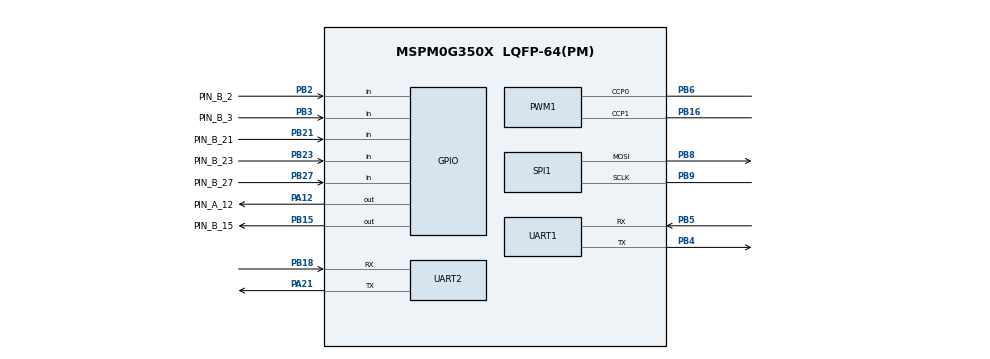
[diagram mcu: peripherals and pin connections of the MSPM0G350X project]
/**
 * @cliArgs --device "MSPM0G350X" --part "Default" --package "LQFP-64(PM)" --product "mspm0_sdk@2.05.01.00"
 * @versions {"tool":"1.24.0+4110"}
 */

/**
 * Import the modules used in this configuration.
 */
const GPIO   = scripting.addModule("/ti/driverlib/GPIO", {}, false);
const GPIO1  = GPIO.addInstance();
const GPIO2  = GPIO.addInstance();
const GPIO3  = GPIO.addInstance();
const GPIO4  = GPIO.addInstance();
const GPIO5  = GPIO.addInstance();
const GPIO6  = GPIO.addInstance();
const PWM    = scripting.addModule("/ti/driverlib/PWM", {}, false);
const PWM1   = PWM.addInstance();
const SPI    = scripting.addModule("/ti/driverlib/SPI", {}, false);
const SPI1   = SPI.addInstance();
const SYSCTL = scripting.addModule("/ti/driverlib/SYSCTL");
const UART   = scripting.addModule("/ti/driverlib/UART", {}, false);
const UART1  = UART.addInstance();
const UART2  = UART.addInstance();

/**
 * Write custom configuration values to the imported modules.
 */
const divider9       = system.clockTree["UDIV"];
divider9.divideValue = 2;

const gate7  = system.clockTree["MFCLKGATE"];
gate7.enable = true;

const mux4       = system.clockTree["EXHFMUX"];
mux4.inputSelect = "EXHFMUX_XTAL";

const mux8       = system.clockTree["HSCLKMUX"];
mux8.inputSelect = "HSCLKMUX_SYSPLL2X";

const mux12       = system.clockTree["SYSPLLMUX"];
mux12.inputSelect = "zSYSPLLMUX_HFCLK";

const pinFunction4       = system.clockTree["HFXT"];
pinFunction4.inputFreq   = 40;
pinFunction4.enable      = true;
pinFunction4.HFXTStartup = 10;

GPIO1.port                          = "PORTB";
GPIO1.$name                         = "GPIO_GRP_LED";
GPIO1.associatedPins[0].assignedPin = "22";
GPIO1.associatedPins[0].$name       = "PIN_B_22";

const Board = scripting.addModule("/ti/driverlib/Board", {}, false);

GPIO2.$name                          = "GPIO_GRP_MOTOR";
GPIO2.associatedPins.create(2);
GPIO2.associatedPins[0].$name        = "PIN_A_12";
GPIO2.associatedPins[0].assignedPort = "PORTA";
GPIO2.associatedPins[0].assignedPin  = "12";
GPIO2.associatedPins[0].pin.$assign  = "PA12";
GPIO2.associatedPins[1].$name        = "PIN_B_15";
GPIO2.associatedPins[1].assignedPort = "PORTB";
GPIO2.associatedPins[1].assignedPin  = "15";
GPIO2.associatedPins[1].pin.$assign  = "PB15";

GPIO3.$name                         = "GPIO_GRP_IRS";
GPIO3.port                          = "PORTA";
GPIO3.associatedPins.create(4);
GPIO3.associatedPins[0].assignedPin = "23";
GPIO3.associatedPins[0].$name       = "PIN_A_24";
GPIO3.associatedPins[1].assignedPin = "25";
GPIO3.associatedPins[1].$name       = "PIN_A_25";
GPIO3.associatedPins[2].assignedPin = "27";
GPIO3.associatedPins[2].$name       = "PIN_A_26";
GPIO3.associatedPins[3].direction   = "INPUT";
GPIO3.associatedPins[3].assignedPin = "29";
GPIO3.associatedPins[3].$name       = "PIN_A_27";

GPIO4.$name                         = "GPIO_GRP_LCD";
GPIO4.port                          = "PORTB";
GPIO4.associatedPins.create(4);
GPIO4.associatedPins[0].assignedPin = "10";
GPIO4.associatedPins[0].ioStructure = "SD";
GPIO4.associatedPins[0].$name       = "PIN_B_10";
GPIO4.associatedPins[1].assignedPin = "11";
GPIO4.associatedPins[1].ioStructure = "SD";
GPIO4.associatedPins[1].$name       = "PIN_B_11";
GPIO4.associatedPins[2].assignedPin = "14";
GPIO4.associatedPins[2].ioStructure = "SD";
GPIO4.associatedPins[2].$name       = "PIN_B_14";
GPIO4.associatedPins[3].assignedPin = "26";
GPIO4.associatedPins[3].ioStructure = "SD";
GPIO4.associatedPins[3].$name       = "PIN_B_26";

GPIO5.$name                         = "GPIO_GRP_ENCODER";
GPIO5.port                          = "PORTB";
GPIO5.associatedPins.create(4);
GPIO5.associatedPins[0].$name       = "PIN_B_2";
GPIO5.associatedPins[0].assignedPin = "2";
GPIO5.associatedPins[0].direction   = "INPUT";
GPIO5.associatedPins[0].interruptEn = true;
GPIO5.associatedPins[0].polarity    = "RISE";
GPIO5.associatedPins[0].pin.$assign = "PB2";
GPIO5.associatedPins[1].$name       = "PIN_B_3";
GPIO5.associatedPins[1].assignedPin = "3";
GPIO5.associatedPins[1].direction   = "INPUT";
GPIO5.associatedPins[1].pin.$assign = "PB3";
GPIO5.associatedPins[2].$name       = "PIN_B_23";
GPIO5.associatedPins[2].assignedPin = "23";
GPIO5.associatedPins[2].direction   = "INPUT";
GPIO5.associatedPins[2].interruptEn = true;
GPIO5.associatedPins[2].polarity    = "RISE";
GPIO5.associatedPins[2].pin.$assign = "PB23";
GPIO5.associatedPins[3].$name       = "PIN_B_27";
GPIO5.associatedPins[3].assignedPin = "27";
GPIO5.associatedPins[3].direction   = "INPUT";
GPIO5.associatedPins[3].pin.$assign = "PB27";

GPIO6.$name                              = "GPIO_GRP_KEY";
GPIO6.port                               = "PORTB";
GPIO6.associatedPins[0].$name            = "PIN_B_21";
GPIO6.associatedPins[0].assignedPin      = "21";
GPIO6.associatedPins[0].direction        = "INPUT";
GPIO6.associatedPins[0].internalResistor = "PULL_UP";
GPIO6.associatedPins[0].pin.$assign      = "PB21";

PWM1.$name                      = "PWM_0";
PWM1.clockPrescale              = 20;
PWM1.pwmMode                    = "EDGE_ALIGN_UP";
PWM1.clockDivider               = 2;
PWM1.peripheral.$assign         = "TIMG8";
PWM1.peripheral.ccp0Pin.$assign = "PB6";
PWM1.peripheral.ccp1Pin.$assign = "PB16";
PWM1.PWM_CHANNEL_0.$name        = "ti_driverlib_pwm_PWMTimerCC0";
PWM1.PWM_CHANNEL_1.$name        = "ti_driverlib_pwm_PWMTimerCC1";
PWM1.ccp0PinConfig.$name        = "ti_driverlib_gpio_GPIOPinGeneric2";
PWM1.ccp1PinConfig.$name        = "ti_driverlib_gpio_GPIOPinGeneric3";

SPI1.targetBitRate                         = 1000000;
SPI1.frameFormat                           = "MOTO3";
SPI1.phase                                 = "1";
SPI1.polarity                              = "1";
SPI1.$name                                 = "SPI_1";
SPI1.rxFifoThreshold                       = "DL_SPI_RX_FIFO_LEVEL_ONE_FRAME";
SPI1.txFifoThreshold                       = "DL_SPI_TX_FIFO_LEVEL_ONE_FRAME";
SPI1.direction                             = "PICO";
SPI1.enabledDMAEvent2Triggers              = "DL_SPI_DMA_INTERRUPT_TX";
SPI1.enabledInterrupts                     = ["DMA_DONE_TX","TX_EMPTY"];
SPI1.sclkPinConfig.direction               = scripting.forceWrite("OUTPUT");
SPI1.sclkPinConfig.onlyInternalResistor    = scripting.forceWrite(false);
SPI1.sclkPinConfig.passedPeripheralType    = scripting.forceWrite("Digital");
SPI1.sclkPinConfig.$name                   = "ti_driverlib_gpio_GPIOPinGeneric4";
SPI1.mosiPinConfig.direction               = scripting.forceWrite("OUTPUT");
SPI1.mosiPinConfig.hideOutputInversion     = scripting.forceWrite(false);
SPI1.mosiPinConfig.onlyInternalResistor    = scripting.forceWrite(false);
SPI1.mosiPinConfig.passedPeripheralType    = scripting.forceWrite("Digital");
SPI1.mosiPinConfig.$name                   = "ti_driverlib_gpio_GPIOPinGeneric5";
SPI1.peripheral.$assign                    = "SPI1";
SPI1.peripheral.sclkPin.$assign            = "PB9";
SPI1.peripheral.mosiPin.$assign            = "PB8";
SPI1.DMA_CHANNEL_EVENT2.$name              = "DMA_CH2";
SPI1.DMA_CHANNEL_EVENT2.srcLength          = "BYTE";
SPI1.DMA_CHANNEL_EVENT2.dstLength          = "BYTE";
SPI1.DMA_CHANNEL_EVENT2.addressMode        = "b2f";
SPI1.DMA_CHANNEL_EVENT2.peripheral.$assign = "DMA_CH2";

SYSCTL.forceDefaultClkConfig = true;
SYSCTL.clockTreeEn           = true;
scripting.suppress("For best practices when the CPUCLK is running at 32MHz and above, clear the flash status bit using DL_FlashCTL_executeClearStatus\\(\\) before executing any flash operation\\. Otherwise there may be false positives\\.", SYSCTL);

UART1.targetBaudRate                    = 100000;
UART1.uartClkSrc                        = "MFCLK";
UART1.enableFIFO                        = true;
UART1.rxFifoThreshold                   = "DL_UART_RX_FIFO_LEVEL_ONE_ENTRY";
UART1.enabledDMARXTriggers              = "DL_UART_DMA_INTERRUPT_RX";
UART1.txFifoThreshold                   = "DL_UART_TX_FIFO_LEVEL_ONE_ENTRY";
UART1.enabledDMATXTriggers              = "DL_UART_DMA_INTERRUPT_TX";
UART1.enabledInterrupts                 = ["DMA_DONE_RX","DMA_DONE_TX","EOT_DONE","RX_TIMEOUT_ERROR"];
UART1.$name                             = "UART_1";
UART1.peripheral.$assign                = "UART1";
UART1.peripheral.rxPin.$assign          = "PB5";
UART1.peripheral.txPin.$assign          = "PB4";
UART1.txPinConfig.direction             = scripting.forceWrite("OUTPUT");
UART1.txPinConfig.hideOutputInversion   = scripting.forceWrite(false);
UART1.txPinConfig.onlyInternalResistor  = scripting.forceWrite(false);
UART1.txPinConfig.passedPeripheralType  = scripting.forceWrite("Digital");
UART1.txPinConfig.$name                 = "ti_driverlib_gpio_GPIOPinGeneric0";
UART1.rxPinConfig.hideOutputInversion   = scripting.forceWrite(false);
UART1.rxPinConfig.onlyInternalResistor  = scripting.forceWrite(false);
UART1.rxPinConfig.passedPeripheralType  = scripting.forceWrite("Digital");
UART1.rxPinConfig.$name                 = "ti_driverlib_gpio_GPIOPinGeneric1";
UART1.DMA_CHANNEL_RX.$name              = "DMA_CH0";
UART1.DMA_CHANNEL_RX.addressMode        = "f2b";
UART1.DMA_CHANNEL_RX.srcLength          = "BYTE";
UART1.DMA_CHANNEL_RX.dstLength          = "BYTE";
UART1.DMA_CHANNEL_RX.peripheral.$assign = "DMA_CH0";
UART1.DMA_CHANNEL_TX.$name              = "DMA_CH1";
UART1.DMA_CHANNEL_TX.addressMode        = "b2f";
UART1.DMA_CHANNEL_TX.srcLength          = "BYTE";
UART1.DMA_CHANNEL_TX.dstLength          = "BYTE";
UART1.DMA_CHANNEL_TX.peripheral.$assign = "DMA_CH1";

UART2.$name                            = "UART_2";
UART2.targetBaudRate                   = 115200;
UART2.enabledInterrupts                = ["RX","RX_TIMEOUT_ERROR"];
UART2.uartClkSrc                       = "MFCLK";
UART2.peripheral.$assign               = "UART2";
UART2.peripheral.rxPin.$assign         = "PB18";
UART2.peripheral.txPin.$assign         = "PA21";
UART2.txPinConfig.direction            = scripting.forceWrite("OUTPUT");
UART2.txPinConfig.hideOutputInversion  = scripting.forceWrite(false);
UART2.txPinConfig.onlyInternalResistor = scripting.forceWrite(false);
UART2.txPinConfig.passedPeripheralType = scripting.forceWrite("Digital");
UART2.txPinConfig.$name                = "ti_driverlib_gpio_GPIOPinGeneric7";
UART2.rxPinConfig.hideOutputInversion  = scripting.forceWrite(false);
UART2.rxPinConfig.onlyInternalResistor = scripting.forceWrite(false);
UART2.rxPinConfig.passedPeripheralType = scripting.forceWrite("Digital");
UART2.rxPinConfig.$name                = "ti_driverlib_gpio_GPIOPinGeneric8";

/**
 * Pinmux solution for unlocked pins/peripherals. This ensures that minor changes to the automatic solver in a future
 * version of the tool will not impact the pinmux you originally saw.  These lines can be completely deleted in order to
 * re-solve from scratch.
 */
pinFunction4.peripheral.$suggestSolution           = "SYSCTL";
pinFunction4.peripheral.hfxInPin.$suggestSolution  = "PA5";
pinFunction4.peripheral.hfxOutPin.$suggestSolution = "PA6";
GPIO1.associatedPins[0].pin.$suggestSolution       = "PB22";
Board.peripheral.$suggestSolution                  = "DEBUGSS";
Board.peripheral.swclkPin.$suggestSolution         = "PA20";
Board.peripheral.swdioPin.$suggestSolution         = "PA19";
GPIO3.associatedPins[0].pin.$suggestSolution       = "PA23";
GPIO3.associatedPins[1].pin.$suggestSolution       = "PA25";
GPIO3.associatedPins[2].pin.$suggestSolution       = "PA27";
GPIO3.associatedPins[3].pin.$suggestSolution       = "PA29";
GPIO4.associatedPins[0].pin.$suggestSolution       = "PB10";
GPIO4.associatedPins[1].pin.$suggestSolution       = "PB11";
GPIO4.associatedPins[2].pin.$suggestSolution       = "PB14";
GPIO4.associatedPins[3].pin.$suggestSolution       = "PB26";
